# LPC800 register map
File version: 0.2
CPU: CM0 r0p0, little endian, no MPU, no FPU, 2 interrupt priority bits
Registers are 32-bit, read-write, reset 0x0 unless marked. A register's access mark holds for its fields unless they carry their own. Offsets are from the block's base; [hi:lo] are bit positions; {n}, {i} and the like mark numbered series; 'fields as' and 'values as' point back to an identical list.

## IOCON — I/O configuration (IOCON)
Base 0x40044000
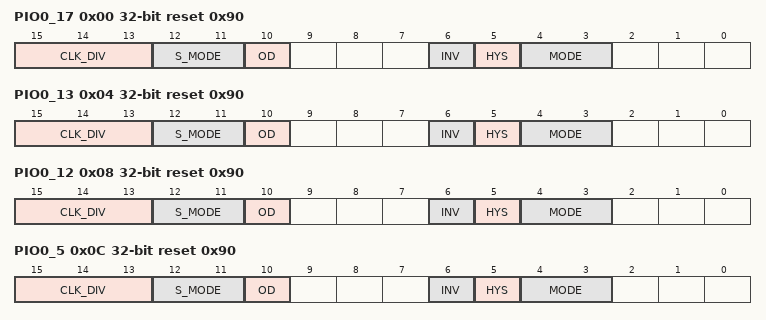
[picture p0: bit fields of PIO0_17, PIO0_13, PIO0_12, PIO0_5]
0x00 PIO0_17 reset 0x90 — I/O configuration for pin PIO0_17
  [15:13] CLK_DIV — Select peripheral clock divider for input filter sampling clock. Value 0x7 is reserved.
    {v}=IOCONFILTRCLKDIV{v}_ (v=0..6)
  [12:11] S_MODE — Digital filter sample mode.
    0=BYPASS_INPUT_FILTER_; 1=1_CLOCK_CYCLE_INPUT (1 clock cycle. Input pulses shorter than one filter clock are rejected.); 2=2_CLOCK_CYCLES_INPU (2 clock cycles. Input pulses shorter than two filter clocks are rejected.); 3=3_CLOCK_CYCLES_INPU (3 clock cycles. Input pulses shorter than three filter clocks are rejected.)
  [10] OD — Open-drain mode.
    0=DISABLE_; 1=OPEN_DRAIN_MODE_ENAB (Open-drain mode enabled. This is not a true open-drain mode.)
  [6] INV — Invert input
    0=INPUT_NOT_INVERTED_ (Input not inverted (HIGH on pin reads as 1; LOW on pin reads as 0).); 1=INPUT_INVERTED_HIGH (Input inverted (HIGH on pin reads as 0, LOW on pin reads as 1).)
  [5] HYS — Hysteresis.
    0=DISABLE_; 1=ENABLE_
  [4:3] MODE — Selects function mode (on-chip pull-up/pull-down resistor control).
    0=INACTIVE_NO_PULL_DO (Inactive (no pull-down/pull-up resistor enabled).); 1=PULL_DOWN_RESISTOR_E (Pull-down resistor enabled.); 2=PULL_UP_RESISTOR_ENA (Pull-up resistor enabled.); 3=REPEATER_MODE_
0x04 PIO0_13 reset 0x90 — I/O configuration for pin PIO0_13
  fields as PIO0_17
0x08 PIO0_12 reset 0x90 — I/O configuration for pin PIO0_12
  fields as PIO0_17
0x0C PIO0_5 reset 0x90 — I/O configuration for pin PIO0_5/RESET
  fields as PIO0_17
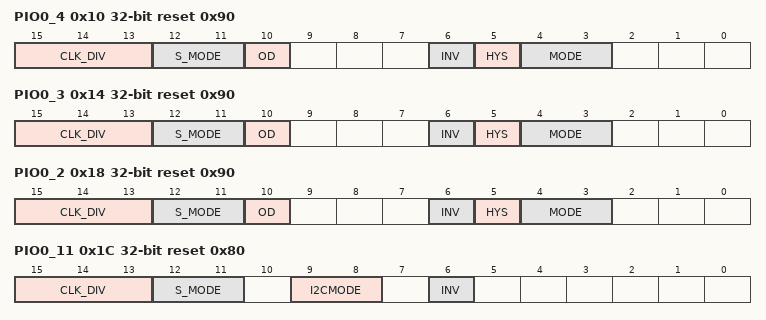
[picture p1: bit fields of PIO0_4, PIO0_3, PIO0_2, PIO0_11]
0x10 PIO0_4 reset 0x90 — I/O configuration for pin PIO0_4
  fields as PIO0_17
0x14 PIO0_3 reset 0x90 — I/O configuration for pin PIO0_3/SWCLK
  [15:13] CLK_DIV — Select peripheral clock divider for input filter sampling clock. Value 0x7 is reserved.
    {v}=IOCONFILTRCLKDIV{v}_ (v=0..6)
  [12:11] S_MODE — Digital filter sample mode.
    values as PIO0_17.S_MODE
  [10] OD — Open-drain mode.
    values as PIO0_17.OD
  [6] INV — Invert input.
    values as PIO0_17.INV
  [5] HYS — Hysteresis.
    0=DISABLE_; 1=ENABLE_
  [4:3] MODE — Selects function mode (on-chip pull-up/pull-down resistor control).
    values as PIO0_17.MODE
0x18 PIO0_2 reset 0x90 — I/O configuration for pin PIO0_2/SWDIO
  fields as PIO0_3
0x1C PIO0_11 reset 0x80 — I/O configuration for pin PIO0_11. This is the pin configuration for the true open-drain pin.
  [15:13] CLK_DIV — Select peripheral clock divider for input filter sampling clock. Value 0x7 is reserved.
    {v}=IOCONFILTRCLKDIV{v}_ (v=0..6)
  [12:11] S_MODE — Digital filter sample mode.
    values as PIO0_17.S_MODE
  [9:8] I2CMODE — Selects I2C mode. Select Standard mode (I2CMODE = 00, default) or Standard I/O functionality (I2CMODE = 01) if the pin function is GPIO (FUNC = 000).
    0=STANDARD_MODE (Standard mode/ Fast-mode I2C.); 1=STANDARD_IO (Standard I/O functionality); 2=FAST_MODE_PLUS_I2C
  [6] INV — Invert input
    values as PIO0_17.INV
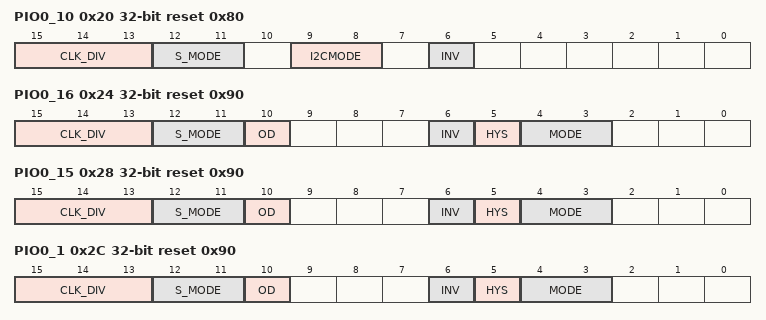
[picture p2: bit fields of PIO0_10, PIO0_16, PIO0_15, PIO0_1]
0x20 PIO0_10 reset 0x80 — I/O configuration for pin PIO0_10. This is the pin configuration for the true open-drain pin.
  fields as PIO0_11
0x24 PIO0_16 reset 0x90 — I/O configuration for pin PIO0_16
  fields as PIO0_17
0x28 PIO0_15 reset 0x90 — I/O configuration for pin PIO0_15
  fields as PIO0_17
0x2C PIO0_1 reset 0x90 — I/O configuration for pin PIO0_1/ACMP_I1/CLKIN
  fields as PIO0_17
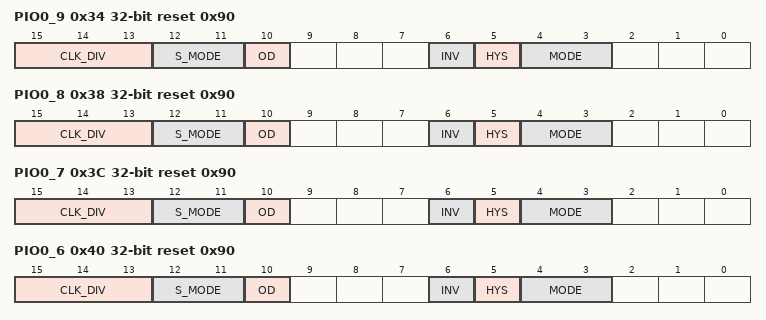
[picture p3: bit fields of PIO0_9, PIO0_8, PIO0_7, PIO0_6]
0x34 PIO0_9 reset 0x90 — I/O configuration for pin PIO0_9/XTALOUT
  fields as PIO0_17
0x38 PIO0_8 reset 0x90 — I/O configuration for pin PIO0_8/XTALIN
  fields as PIO0_17
0x3C PIO0_7 reset 0x90 — I/O configuration for pin PIO0_7
  fields as PIO0_17
0x40 PIO0_6 reset 0x90 — I/O configuration for pin PIO0_6/VDDCMP
  fields as PIO0_17
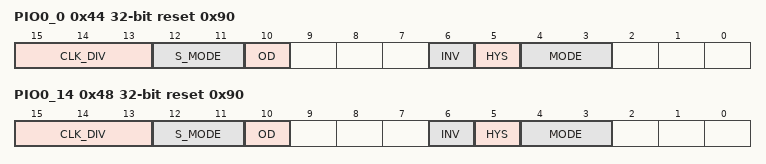
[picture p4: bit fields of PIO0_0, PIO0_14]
0x44 PIO0_0 reset 0x90 — I/O configuration for pin PIO0_0/ACMP_I0
  fields as PIO0_17
0x48 PIO0_14 reset 0x90 — I/O configuration for pin PIO0_14
  fields as PIO0_17
